# ECM3532 register map
Vendor: EtaCompute; Series: ECM35xx; File version: 1.0.0
CPU: CM3 r1p1, little endian, MPU, no FPU, 3 interrupt priority bits
Registers are 32-bit, read-write, reset 0x0 unless marked. A register's access mark holds for its fields unless they carry their own. Offsets are from the block's base; [hi:lo] are bit positions; {n}, {i} and the like mark numbered series.

## FLASH_CTLR — The flash controller module provides capabilities to erase and program the embedded flash memory storage.
Base 0xE0080000
0x00 STATUS — Status bits for the Flash Control Module.
  [0] READY ro — This bit indicates that the controller is ready to receive write data or that a timer count has reached 0.
    1=READY (The flash controller is ready to receive write data and there is no active timer countdown.); 0=NOT_READY (The flash controller is not ready to receive data or that the timer has not completed a count to 0.)
0x04 CONTROLEN — Enable/Disable the flash controller to erase or program the embedded flash.
  [31:0] KEY — Enable the flash controller to drive the flash instance signals by writing the value 0x5c3a1ec9 to this location. A write of any other value will revert control of the flash signals to the M3.
0x10 CONTROL0 — Control bits for the Flash Control Module. This register controls the status power states and signal ownership control.
  [0] LVEN — Indicates to the Flash Memory whether the voltage range is low (0.81 - 1.08V) or high (1.08 - 1.32V).
    1=LOWV (The flash is operating in the low voltages range (0.81 - 1.08V).); 0=HIGHV (The flash is operating in the high voltages range (1.08 - 1.32V).)
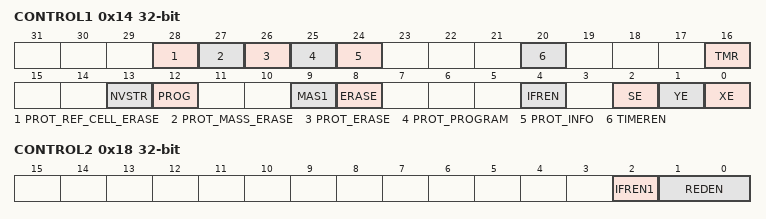
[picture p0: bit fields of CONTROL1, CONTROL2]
0x14 CONTROL1 — Control bits for the Flash Control Module. This is the primary register used to control signals for program and erase operations.
  [28] PROT_REF_CELL_ERASE — Set to one to tell the flash controller to set the protection enables for a reference cell erase operation.
  [27] PROT_MASS_ERASE — Set to one to tell the flash controller to set the protection enables for a mass erase operation.
  [26] PROT_ERASE — Set to one to tell the flash controller to set the protection enables for an erase operation.
  [25] PROT_PROGRAM — Set to one to tell the flash controller to set the protection enables for a program operation
  [24] PROT_INFO — Set to one to tell the flash controller to set the protection enables for an INFO page access(erase or program).
  [20] TIMEREN wo — When set to a 1, the Flash Controller Timer will begin counting down from the value written to the Count Register to 0 at 1uS intervals.
  [16] TMR — This bit controls the TMR pin of the embedded flash. It is only used during the Erase Reference Cell operation and should be set to 1 at all other times.
  [13] NVSTR — This bit controls the NVSTR pin of the embedded flash. It is set or cleared as required for a particular operation.
  [12] PROG — This bit controls the PROG pin of the embedded flash. It is set or cleared as required for a particular operation.
  [9] MAS1 — This bit controls the MAS1 pin of the embedded flash. It is set or cleared as required for a particular operation.
  [8] ERASE — This bit controls the ERASE pin of the embedded flash. It is set or cleared as required for a particular operation.
  [4] IFREN — This bit controls the IFREN pin of the embedded flash. It is set or cleared as required for a particular operation.
  [2] SE — This bit controls the SE pin of the embedded flash. It is set or cleared as required for a particular operation.
  [1] YE — This bit controls the YE pin of the embedded flash. It is set or cleared as required for a particular operation.
  [0] XE — This bit controls the XE pin of the embedded flash. It is set or cleared as required for a particular operation.
0x18 CONTROL2 — Control bits for the Flash Redundancy Modes.
  [2] IFREN1 — This bit enables access to the Flash's Redundant Information Page. NOT USED CURRENTLY
    1=ENABLE (User can access data in the redundant information page.); 0=DISABLE (User can perform normal memory accesses.)
  [1:0] REDEN — This bit enables access to the Flash's Redundant Data Pages. The flash instance supports 2 redundancy pages to improve yield during manufacturing. If utilized, when the user attempts to access a bad page, the REDEN[] bit can be set to allow use of the redundant page. Only one of the 2 bits can be set, the value represents one of two possible redundant pages. NOT CURRENTLY USED
    0=NORMAL (The regular pages of the array are used for accesses.); 1=PAGE0 (Redundant page0 is accessed rather than the normal page for this address.); 2=PAGE1 (Redundant page1 is accessed rather than the normal page for this address.)
0x20 TIMER — 20-bit count value which is used by the Flash Controller Timer. The timer counts at 1uS intervals, and the 20b value give us up to 1S of time.
  [19:0] COUNT — 20-bit count value which is loaded into the controller's timer and then counts to 0 at 1uS increments. The value written to this register is retained and can be reused as needed.
0x30 ADDR — Address of the Flash Memory to write data.
  [31:0] ADDR — The address of the Flash Memory to use for erase, program, and read operations. This is a byte address, although the flash is only accessible at 32b word boundaries.
{0x40+4i} DATA{i} (i=0..3) — 32-bits of data[{32i+31}:{32i}] to be written to or read from the Flash memory.
  [31:0] DATA

## I2S — The I2S Regs provide access to send and receive audio samples from I2S interface.
Base 0x50050100
0x00 CSR — This register configure the i2s settings.
  [0] I2S_EN — Set this bit enable to the I2S.
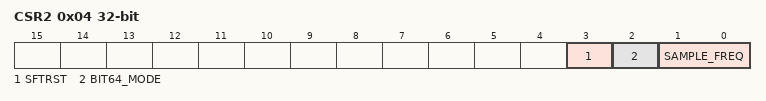
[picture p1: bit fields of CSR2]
0x04 CSR2 — This register configure the i2s settings.
  [3] SFTRST — Soft reset which resets the entire I2S to its POR state.
    1=RST (Reset.)
  [2] BIT64_MODE — Set this bit to set the frame size to 64 bits.
  [1:0] SAMPLE_FREQ — 00: 8ksps, 01: 16ksps, 10: 32ksps, 11: not implemented.

## PDM0 — The Pulse Density Module (PDM) filter engine provides for 2 DMEMs microphones to be attached. The digital microphone PDM streams comes in at 1.024MHz or 2.048MHz yielding either 8Ksps or 16Ksps stereo PCM sample streams.
Base 0x50050200
Same registers: PDM1 0x50050300
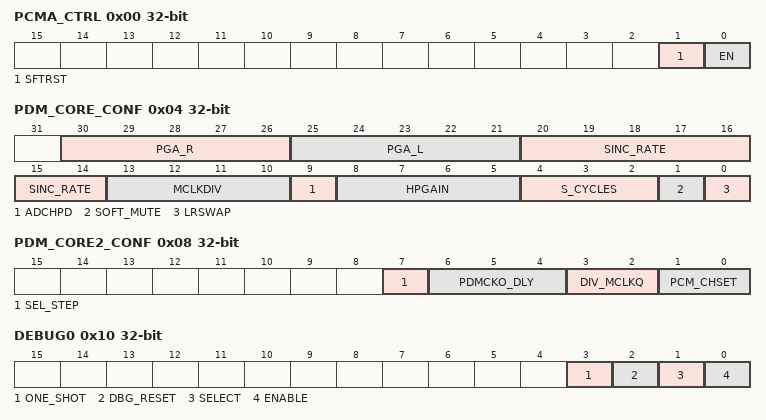
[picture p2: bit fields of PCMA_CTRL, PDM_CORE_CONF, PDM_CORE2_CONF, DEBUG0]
0x00 PCMA_CTRL — Contains the enable bit to start the audio stream.
  [1] SFTRST — Soft reset which resets the entire PDM to its POR state.
    1=RST (Reset.)
  [0] EN — PDM input and PCM output data streaming enable.
    0=DISABLE; 1=ENABLE
0x04 PDM_CORE_CONF — Configuration bits for the PDM-to-PCM core.
  [30:26] PGA_R — Range: -12dB ~ +34.5dB, +1.5dB per step.
    0=M12DB (-12dB); 1=M10P5DB (-10.5dB); 31=34P5DB (+34.5dB)
  [25:21] PGA_L — Range: -12dB ~ +34.5dB, +1.5dB per step.
    0=M12DB (-12dB); 1=M10P5DB (-10.5dB); 31=34P5DB (+34.5dB)
  [20:14] SINC_RATE — FIXME: describe the function.
  [13:10] MCLKDIV — PDMA_CKO frequency divisor. F(PDMA_CKO)=F(MCLK_L)/[MCLKDIV+1].
  [9] ADCHPD — FIXME: describe the function.
  [8:5] HPGAIN — Adjust High-Pass filter coefficients.
  [4:2] S_CYCLES — Set number of PDMA_CKO during gain-setting changes or soft mute.
  [1] SOFT_MUTE — FIXME: describe the function.
    0=DISABLE (Disabled.); 1=ENABLE (Enabled.)
  [0] LRSWAP — Swaps the channel of the input audio samples.
    0=NORMAL (No swap.); 1=SWAP (Swap channel.)
0x08 PDM_CORE2_CONF — Extra configuration bits for the PDM-to-PCM core.
  [7] SEL_STEP — Set fine gain step for smooth PGA or Soft-Mute attenuation transition.
    0=LOW (0.13dB.); 1=HIGH (0.26dB.)
  [6:4] PDMCKO_DLY — PDM_CKO clock phase delay in terms of HMCLKA period to internal Sampler.
    0=NONE (No extra HMCLKA clock cycle delay.); 1=ONE (One extra HMCLKA clock cycle delay.); 7=SEVEN (Seven extra HMCLKA clock cycle delay.)
  [3:2] DIV_MCLKQ — HMCLKA divide-down ratio for generating internal master clock MCLKQ.
    0=BYPASS (F(MCLKQ)=F(HMCLKA).); 1=DIV_BY_1 (F(MCLKQ)=F(HMCLKA)/1.); 2=DIV_BY_2 (F(MCLKQ)=F(HMCLKA)/2.); 3=DIV_BY_3 (F(MCLKQ)=F(HMCLKA)/3.)
  [1:0] PCM_CHSET — Set PCM Output Channels as Mono or Stereo.
    0=DISABLE (Channel disabled.); 1=MONO_L (Mono (left).); 2=MONO_R (Mono (Right).); 3=STEREO
0x0C PDM_CTRL_CONF — Control configuration bits for the PDM-to-PCM core.
  [31:0] PDM_CNTL — For internal use only. Do not write to this register in normal operation.
0x10 DEBUG0 — PDM CORE Debug0
  [3] ONE_SHOT — If 1 we will only capture 31 bits of data and then stop. Setting/clearing DBG_RESET before this is required. Toggle will be one once sampled.
  [2] DBG_RESET — If 1 we hold the shift registers in reset. If 0, data is being captured.
  [1] SELECT — Select data to record. Valid options are: 1:Left Channel data only (normally sampled on rising edge of CKO) 0:Right Channel data only (normally sampled on falling edge of CKO)
  [0] ENABLE — For internal use only. Do not write to this register in normal operation. If 1, the debug logic is running. If 0, it is not.
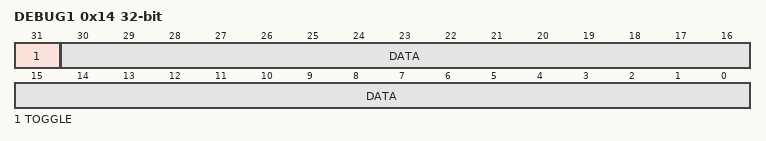
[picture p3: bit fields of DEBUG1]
0x14 DEBUG1 — PDM CORE Debug1
  [31] TOGGLE ro — Changes every 31 bits of sample.
  [30:0] DATA ro — 31 bit sample data.
